# jbr_MDR1986VE1T register map
Registers are 32-bit, access not given, no defined reset value unless marked. A register's access mark holds for its fields unless they carry their own. Addresses are absolute; registers are grouped by the start of their names; [hi:lo] are bit positions; {n}, {i} and the like mark numbered series; 'fields as' and 'values as' point back to an identical list.

## RTC
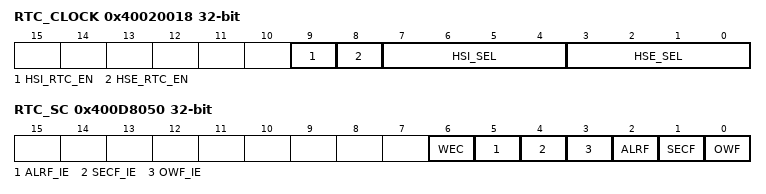
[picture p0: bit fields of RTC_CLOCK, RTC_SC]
0x40020018 RTC_CLOCK
  [9] HSI_RTC_EN, [8] HSE_RTC_EN, [7:4] HSI_SEL, [3:0] HSE_SEL
0x400D8040 RTC_CNT
0x400D8044 RTC_DIV
  [19:0] RTC_DIV
0x400D8048 RTC_PRL
  [19:0] RTC_PRL
0x400D804C RTC_ALRM
0x400D8050 RTC_SC
  [6] WEC, [5] ALRF_IE, [4] SECF_IE, [3] OWF_IE, [2] ALRF, [1] SECF, [0] OWF

## ETH
0x30000000 ETH_Dilimiter 16-bit
0x30000002 ETH_MAC_T 16-bit
0x30000004 ETH_MAC_M 16-bit
0x30000006 ETH_MAC_H 16-bit
{0x30000008+2i} ETH_HASH{i} 16-bit (i=0..3)
0x30000010 ETH_IPG 16-bit
0x30000012 ETH_PSC 16-bit
0x30000014 ETH_BAG 16-bit
0x30000016 ETH_JitterWnd 16-bit
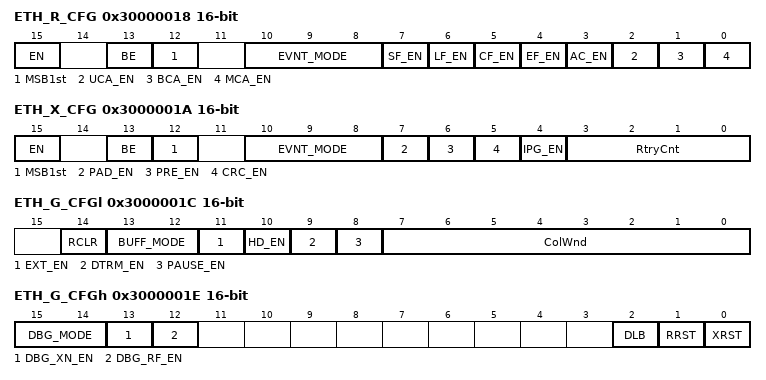
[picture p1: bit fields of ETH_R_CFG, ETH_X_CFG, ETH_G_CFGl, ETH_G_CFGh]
0x30000018 ETH_R_CFG 16-bit
  [15] EN, [13] BE, [12] MSB1st, [10:8] EVNT_MODE, [7] SF_EN, [6] LF_EN, [5] CF_EN, [4] EF_EN, [3] AC_EN, [2] UCA_EN, [1] BCA_EN, [0] MCA_EN
0x3000001A ETH_X_CFG 16-bit
  [15] EN, [13] BE, [12] MSB1st, [10:8] EVNT_MODE, [7] PAD_EN, [6] PRE_EN, [5] CRC_EN, [4] IPG_EN, [3:0] RtryCnt
0x3000001C ETH_G_CFGl 16-bit
  [14] RCLR, [13:12] BUFF_MODE, [11] EXT_EN, [10] HD_EN, [9] DTRM_EN, [8] PAUSE_EN, [7:0] ColWnd
0x3000001E ETH_G_CFGh 16-bit
  [15:14] DBG_MODE, [13] DBG_XN_EN, [12] DBG_RF_EN, [2] DLB, [1] RRST, [0] XRST
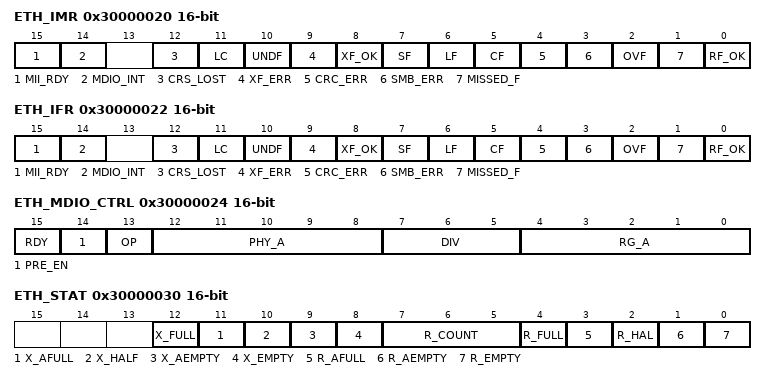
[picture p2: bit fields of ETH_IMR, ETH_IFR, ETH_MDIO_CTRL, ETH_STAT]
0x30000020 ETH_IMR 16-bit
  [15] MII_RDY, [14] MDIO_INT, [12] CRS_LOST, [11] LC, [10] UNDF, [9] XF_ERR, [8] XF_OK, [7] SF, [6] LF, [5] CF, [4] CRC_ERR, [3] SMB_ERR, [2] OVF, [1] MISSED_F, [0] RF_OK
0x30000022 ETH_IFR 16-bit
  fields as ETH_IMR
0x30000024 ETH_MDIO_CTRL 16-bit
  [15] RDY, [14] PRE_EN, [13] OP, [12:8] PHY_A, [7:5] DIV, [4:0] RG_A
0x30000026 ETH_MDIO_DATA 16-bit
0x30000028 ETH_R_Head 16-bit
0x3000002A ETH_X_Tail 16-bit
0x3000002C ETH_R_Tail 16-bit
0x3000002E ETH_X_Head 16-bit
0x30000030 ETH_STAT 16-bit
  [12] X_FULL, [11] X_AFULL, [10] X_HALF, [9] X_AEMPTY, [8] X_EMPTY, [7:5] R_COUNT, [4] R_FULL, [3] R_AFULL, [2] R_HAL, [1] R_AEMPTY, [0] R_EMPTY
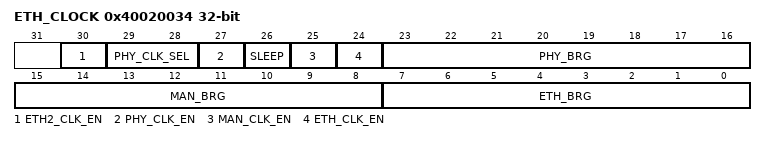
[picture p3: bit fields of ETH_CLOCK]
0x40020034 ETH_CLOCK
  [30] ETH2_CLK_EN, [29:28] PHY_CLK_SEL, [27] PHY_CLK_EN, [26] SLEEP, [25] MAN_CLK_EN, [24] ETH_CLK_EN, [23:16] PHY_BRG, [15:8] MAN_BRG, [7:0] ETH_BRG

## BKP
{0x400D8000+4i} BKP_REG_{i:02} (i=0..9)
0x400D8028 BKP_REG_0A
0x400D802C BKP_REG_0B
0x400D8030 BKP_REG_0C
0x400D8034 BKP_REG_0D
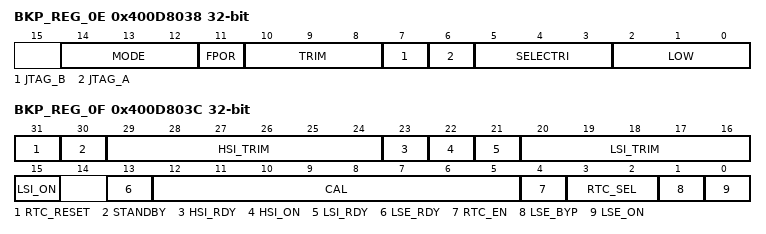
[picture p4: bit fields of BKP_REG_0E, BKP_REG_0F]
0x400D8038 BKP_REG_0E
  [14:12] MODE, [11] FPOR, [10:8] TRIM, [7] JTAG_B, [6] JTAG_A, [5:3] SELECTRI, [2:0] LOW
0x400D803C BKP_REG_0F
  [31] RTC_RESET, [30] STANDBY, [29:24] HSI_TRIM, [23] HSI_RDY, [22] HSI_ON, [21] LSI_RDY, [20:16] LSI_TRIM, [15] LSI_ON, [13] LSE_RDY, [12:5] CAL, [4] RTC_EN, [3:2] RTC_SEL, [1] LSE_BYP, [0] LSE_ON

## SFR
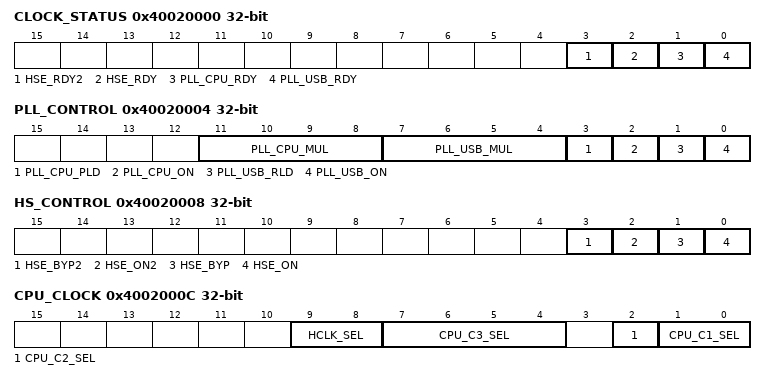
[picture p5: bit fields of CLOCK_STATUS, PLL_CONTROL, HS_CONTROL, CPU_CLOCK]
0x40020000 CLOCK_STATUS
  [3] HSE_RDY2, [2] HSE_RDY, [1] PLL_CPU_RDY, [0] PLL_USB_RDY
0x40020004 PLL_CONTROL
  [11:8] PLL_CPU_MUL, [7:4] PLL_USB_MUL, [3] PLL_CPU_PLD, [2] PLL_CPU_ON, [1] PLL_USB_RLD, [0] PLL_USB_ON
0x40020008 HS_CONTROL
  [3] HSE_BYP2, [2] HSE_ON2, [1] HSE_BYP, [0] HSE_ON
0x4002000C CPU_CLOCK
  [9:8] HCLK_SEL, [7:4] CPU_C3_SEL, [2] CPU_C2_SEL, [1:0] CPU_C1_SEL
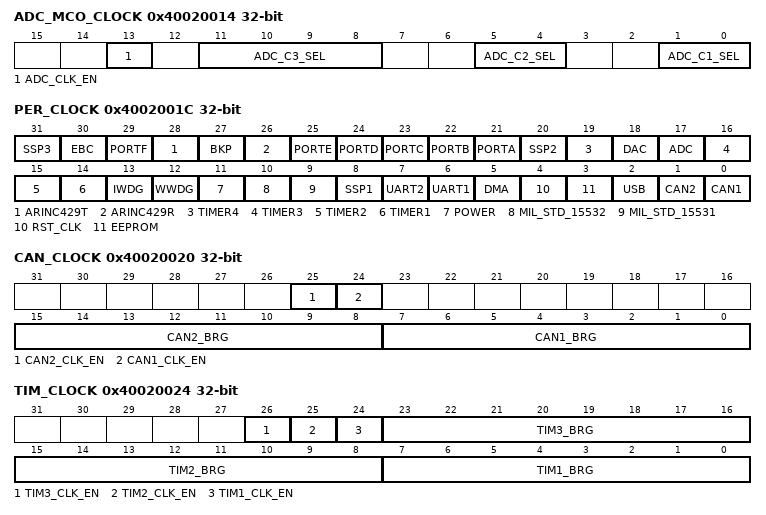
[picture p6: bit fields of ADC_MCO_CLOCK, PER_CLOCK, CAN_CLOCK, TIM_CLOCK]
0x40020014 ADC_MCO_CLOCK
  [13] ADC_CLK_EN, [11:8] ADC_C3_SEL, [5:4] ADC_C2_SEL, [1:0] ADC_C1_SEL
0x4002001C PER_CLOCK
  [31] SSP3, [30] EBC, [29] PORTF, [28] ARINC429T, [27] BKP, [26] ARINC429R, [25] PORTE, [24] PORTD, [23] PORTC, [22] PORTB, [21] PORTA, [20] SSP2, [19] TIMER4, [18] DAC, [17] ADC, [16] TIMER3, [15] TIMER2, [14] TIMER1, [13] IWDG, [12] WWDG, [11] POWER, [10] MIL_STD_15532, [9] MIL_STD_15531, [8] SSP1, [7] UART2, [6] UART1, [5] DMA, [4] RST_CLK, [3] EEPROM, [2] USB, [1] CAN2, [0] CAN1
0x40020020 CAN_CLOCK
  [25] CAN2_CLK_EN, [24] CAN1_CLK_EN, [15:8] CAN2_BRG, [7:0] CAN1_BRG
0x40020024 TIM_CLOCK
  [26] TIM3_CLK_EN, [25] TIM2_CLK_EN, [24] TIM1_CLK_EN, [23:16] TIM3_BRG, [15:8] TIM2_BRG, [7:0] TIM1_BRG
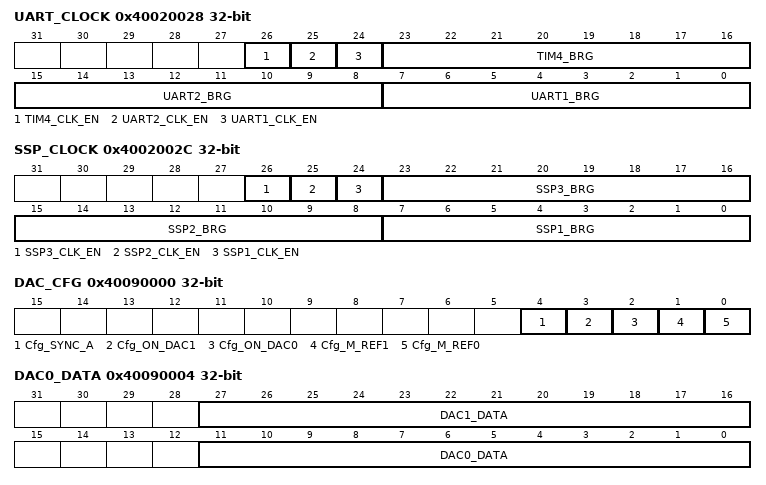
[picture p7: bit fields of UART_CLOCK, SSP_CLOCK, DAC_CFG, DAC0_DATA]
0x40020028 UART_CLOCK
  [26] TIM4_CLK_EN, [25] UART2_CLK_EN, [24] UART1_CLK_EN, [23:16] TIM4_BRG, [15:8] UART2_BRG, [7:0] UART1_BRG
0x4002002C SSP_CLOCK
  [26] SSP3_CLK_EN, [25] SSP2_CLK_EN, [24] SSP1_CLK_EN, [23:16] SSP3_BRG, [15:8] SSP2_BRG, [7:0] SSP1_BRG
0x40028008 CTRL_BASE_PTR
  [31:10] CTRL_BASE_PTR
0x4002800C ALT_CTRL_BASE_PTR
0x4002804C ERR_CLR
  [0] ERR_CLR
0x40088004 ADC2_CFG
  [17] ADC1_OP
0x40090000 DAC_CFG
  [4] Cfg_SYNC_A, [3] Cfg_ON_DAC1, [2] Cfg_ON_DAC0, [1] Cfg_M_REF1, [0] Cfg_M_REF0
0x40090004 DAC0_DATA
  [27:16] DAC1_DATA, [11:0] DAC0_DATA
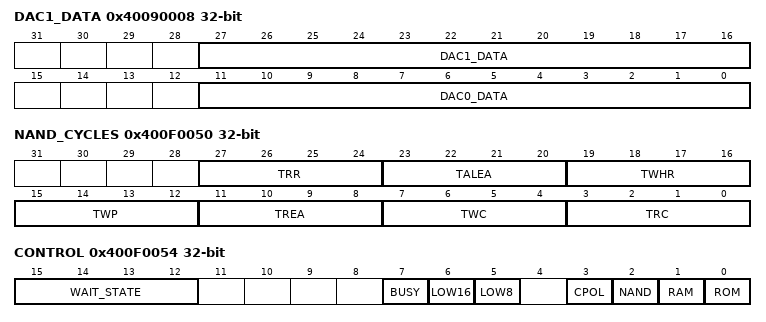
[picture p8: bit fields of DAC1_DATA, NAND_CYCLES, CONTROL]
0x40090008 DAC1_DATA
  [27:16] DAC1_DATA, [11:0] DAC0_DATA
0x400F0050 NAND_CYCLES
  [27:24] TRR, [23:20] TALEA, [19:16] TWHR, [15:12] TWP, [11:8] TREA, [7:4] TWC, [3:0] TRC
0x400F0054 CONTROL
  [15:12] WAIT_STATE, [7] BUSY, [6] LOW16, [5] LOW8, [3] CPOL, [2] NAND, [1] RAM, [0] ROM
